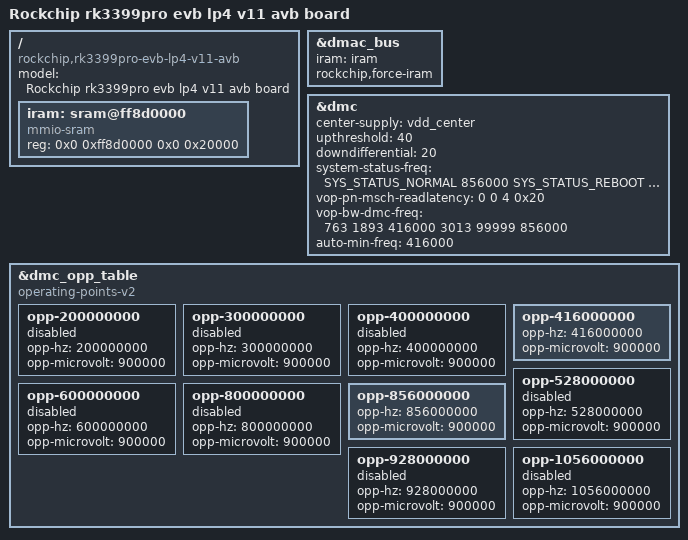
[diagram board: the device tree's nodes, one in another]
// SPDX-License-Identifier: (GPL-2.0+ OR MIT)
/*
 * Copyright (c) 2018 Fuzhou Rockchip Electronics Co., Ltd
 *
 */

/dts-v1/;
#include "rk3399pro-evb-v11-avb.dts"

/ {
	model = "Rockchip rk3399pro evb lp4 v11 avb board";
	compatible = "rockchip,rk3399pro-evb-lp4-v11-avb", "rockchip,rk3399pro";

	/* first 64k(0xff8c0000~0xff8d0000) for ddr and suspend */
	iram: sram@ff8d0000 {
		compatible = "mmio-sram";
		reg = <0x0 0xff8d0000 0x0 0x20000>; /* 128k */
	};
};

&dmac_bus {
	iram = <&iram>;
	rockchip,force-iram;
};

&dmc {
	status = "okay";
	center-supply = <&vdd_center>;
	upthreshold = <40>;
	downdifferential = <20>;
	system-status-freq = <
		/*system status         freq(KHz)*/
		SYS_STATUS_NORMAL       856000
		SYS_STATUS_REBOOT       416000
		SYS_STATUS_SUSPEND      416000
		SYS_STATUS_VIDEO_1080P  416000
		SYS_STATUS_VIDEO_4K     856000
		SYS_STATUS_VIDEO_4K_10B 856000
		SYS_STATUS_PERFORMANCE  856000
		SYS_STATUS_BOOST        856000
		SYS_STATUS_DUALVIEW     856000
		SYS_STATUS_ISP          856000
	>;
	vop-pn-msch-readlatency = <
	/* plane_number  readlatency */
		0	0
		4	0x20
	>;
	vop-bw-dmc-freq = <
	/* min_bw(MB/s) max_bw(MB/s) freq(KHz) */
		763     1893     416000
		3013    99999    856000
	>;
	auto-min-freq = <416000>;
};

&dmc_opp_table {
	compatible = "operating-points-v2";

	opp-200000000 {
		opp-hz = /bits/ 64 <200000000>;
		opp-microvolt = <900000>;
		status = "disabled";
	};
	opp-300000000 {
		opp-hz = /bits/ 64 <300000000>;
		opp-microvolt = <900000>;
		status = "disabled";
	};
	opp-400000000 {
		opp-hz = /bits/ 64 <400000000>;
		opp-microvolt = <900000>;
		status = "disabled";
	};
	opp-416000000 {
		opp-hz = /bits/ 64 <416000000>;
		opp-microvolt = <900000>;
	};
	opp-528000000 {
		opp-hz = /bits/ 64 <528000000>;
		opp-microvolt = <900000>;
		status = "disabled";
	};
	opp-600000000 {
		opp-hz = /bits/ 64 <600000000>;
		opp-microvolt = <900000>;
		status = "disabled";
	};
	opp-800000000 {
		opp-hz = /bits/ 64 <800000000>;
		opp-microvolt = <900000>;
		status = "disabled";
	};
	opp-856000000 {
		opp-hz = /bits/ 64 <856000000>;
		opp-microvolt = <900000>;
	};
	opp-928000000 {
		opp-hz = /bits/ 64 <928000000>;
		opp-microvolt = <900000>;
		status = "disabled";
	};
	opp-1056000000 {
		opp-hz = /bits/ 64 <1056000000>;
		opp-microvolt = <900000>;
		status = "disabled";
	};
};

